# TM4C129ENCPDT register map
File version: 1.0
CPU: CORTEX_M4 1.0, other endian, MPU, FPU, 3 interrupt priority bits
Registers are 32-bit, read-write, reset 0x0 unless marked. A register's access mark holds for its fields unless they carry their own. Offsets are from the block's base; [hi:lo] are bit positions; {n}, {i} and the like mark numbered series.

## FLASH_CTRL — FLASH register offsets
Base 0x400FD000
0x00 FLASH_FMA — Flash Memory Address
  [19:0] FLASH_FMA_OFFSET — [19:0] Address Offset
0x04 FLASH_FMD — Flash Memory Data
  [31:0] FLASH_FMD_DATA — [31:0] Data Value
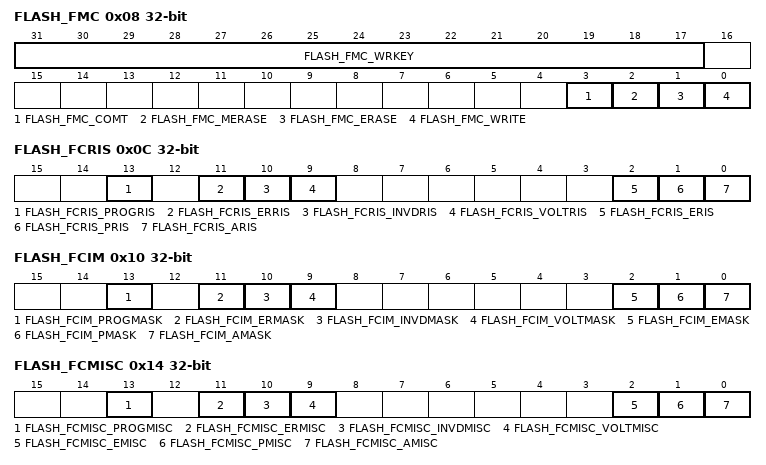
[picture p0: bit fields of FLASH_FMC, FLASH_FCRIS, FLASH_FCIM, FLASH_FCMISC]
0x08 FLASH_FMC — Flash Memory Control
  [31:17] FLASH_FMC_WRKEY — [31:17] FLASH write key
  [3] FLASH_FMC_COMT — [3:3] Commit Register Value
  [2] FLASH_FMC_MERASE — [2:2] Mass Erase Flash Memory
  [1] FLASH_FMC_ERASE — [1:1] Erase a Page of Flash Memory
  [0] FLASH_FMC_WRITE — [0:0] Write a Word into Flash Memory
0x0C FLASH_FCRIS — Flash Controller Raw Interrupt Status
  [13] FLASH_FCRIS_PROGRIS — [13:13] Program Verify Error Raw Interrupt Status
  [11] FLASH_FCRIS_ERRIS — [11:11] Erase Verify Error Raw Interrupt Status
  [10] FLASH_FCRIS_INVDRIS — [10:10] Invalid Data Raw Interrupt Status
  [9] FLASH_FCRIS_VOLTRIS — [9:9] Pump Voltage Raw Interrupt Status
  [2] FLASH_FCRIS_ERIS — [2:2] EEPROM Raw Interrupt Status
  [1] FLASH_FCRIS_PRIS — [1:1] Programming Raw Interrupt Status
  [0] FLASH_FCRIS_ARIS — [0:0] Access Raw Interrupt Status
0x10 FLASH_FCIM — Flash Controller Interrupt Mask
  [13] FLASH_FCIM_PROGMASK — [13:13] PROGVER Interrupt Mask
  [11] FLASH_FCIM_ERMASK — [11:11] ERVER Interrupt Mask
  [10] FLASH_FCIM_INVDMASK — [10:10] Invalid Data Interrupt Mask
  [9] FLASH_FCIM_VOLTMASK — [9:9] VOLT Interrupt Mask
  [2] FLASH_FCIM_EMASK — [2:2] EEPROM Interrupt Mask
  [1] FLASH_FCIM_PMASK — [1:1] Programming Interrupt Mask
  [0] FLASH_FCIM_AMASK — [0:0] Access Interrupt Mask
0x14 FLASH_FCMISC — Flash Controller Masked Interrupt Status and Clear
  [13] FLASH_FCMISC_PROGMISC — [13:13] PROGVER Masked Interrupt Status and Clear
  [11] FLASH_FCMISC_ERMISC — [11:11] ERVER Masked Interrupt Status and Clear
  [10] FLASH_FCMISC_INVDMISC — [10:10] Invalid Data Masked Interrupt Status and Clear
  [9] FLASH_FCMISC_VOLTMISC — [9:9] VOLT Masked Interrupt Status and Clear
  [2] FLASH_FCMISC_EMISC — [2:2] EEPROM Masked Interrupt Status and Clear
  [1] FLASH_FCMISC_PMISC — [1:1] Programming Masked Interrupt Status and Clear
  [0] FLASH_FCMISC_AMISC — [0:0] Access Masked Interrupt Status and Clear
0x20 FLASH_FMC2 — Flash Memory Control 2
  [0] FLASH_FMC2_WRBUF — [0:0] Buffered Flash Memory Write
0x30 FLASH_FWBVAL — Flash Write Buffer Valid
  [31:0] FLASH_FWBVAL_FWB — [31:0] Flash Memory Write Buffer
0x3C FLASH_FLPEKEY — Flash Program/Erase Key
  [15:0] FLASH_FLPEKEY_PEKEY — [15:0] Key Value
0x100 FLASH_FWBN — Flash Write Buffer n
  [31:0] FLASH_FWBN_DATA — [31:0] Data
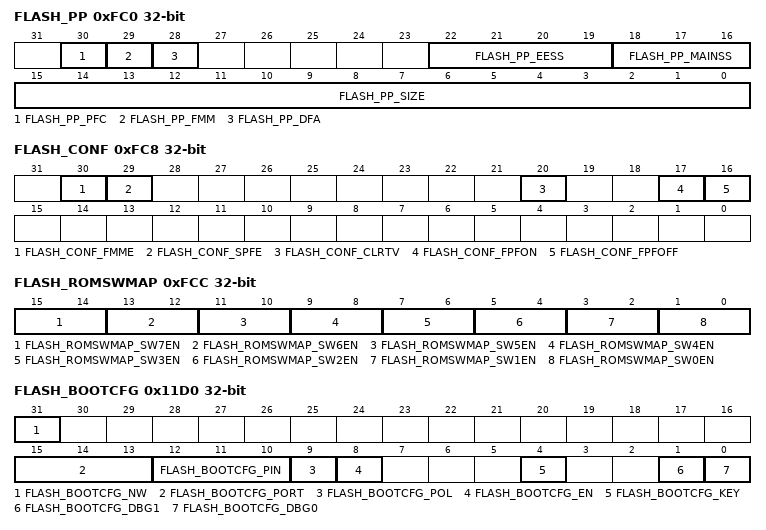
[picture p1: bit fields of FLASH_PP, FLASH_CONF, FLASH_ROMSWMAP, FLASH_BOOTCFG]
0xFC0 FLASH_PP — Flash Peripheral Properties
  [30] FLASH_PP_PFC — [30:30] Prefetch Buffer Mode
  [29] FLASH_PP_FMM — [29:29] Flash Mirror Mode
  [28] FLASH_PP_DFA — [28:28] DMA Flash Access
  [22:19] FLASH_PP_EESS — [22:19] EEPROM Sector Size of the physical bank
    0=FLASH_PP_EESS_1KB (1 KB); 0x80000=FLASH_PP_EESS_2KB (2 KB); 0x100000=FLASH_PP_EESS_4KB (4 KB); 0x180000=FLASH_PP_EESS_8KB (8 KB)
  [18:16] FLASH_PP_MAINSS — [18:16] Flash Sector Size of the physical bank
    0=FLASH_PP_MAINSS_1KB (1 KB); 0x10000=FLASH_PP_MAINSS_2KB (2 KB); 0x20000=FLASH_PP_MAINSS_4KB (4 KB); 0x30000=FLASH_PP_MAINSS_8KB (8 KB); 0x40000=FLASH_PP_MAINSS_16KB (16 KB)
  [15:0] FLASH_PP_SIZE — [15:0] Flash Size
    0x1FF=FLASH_PP_SIZE_1MB (1024 KB of Flash)
0xFC4 FLASH_SSIZE — SRAM Size
  [15:0] FLASH_SSIZE_SIZE — [15:0] SRAM Size
    0x3FF=FLASH_SSIZE_SIZE_256KB (256 KB of SRAM)
0xFC8 FLASH_CONF — Flash Configuration Register
  [30] FLASH_CONF_FMME — [30:30] Flash Mirror Mode Enable
  [29] FLASH_CONF_SPFE — [29:29] Single Prefetch Mode Enable
  [20] FLASH_CONF_CLRTV — [20:20] Clear Valid Tags
  [17] FLASH_CONF_FPFON — [17:17] Force Prefetch On
  [16] FLASH_CONF_FPFOFF — [16:16] Force Prefetch Off
0xFCC FLASH_ROMSWMAP — ROM Software Map
  [15:14] FLASH_ROMSWMAP_SW7EN — [15:14] ROM SW Region 7 Availability
    0=FLASH_ROMSWMAP_SW7EN_NOTVIS (Software region not available to the core); 0x4000=FLASH_ROMSWMAP_SW7EN_CORE (Region available to core)
  [13:12] FLASH_ROMSWMAP_SW6EN — [13:12] ROM SW Region 6 Availability
    0=FLASH_ROMSWMAP_SW6EN_NOTVIS (Software region not available to the core); 0x1000=FLASH_ROMSWMAP_SW6EN_CORE (Region available to core)
  [11:10] FLASH_ROMSWMAP_SW5EN — [11:10] ROM SW Region 5 Availability
    0=FLASH_ROMSWMAP_SW5EN_NOTVIS (Software region not available to the core); 0x400=FLASH_ROMSWMAP_SW5EN_CORE (Region available to core)
  [9:8] FLASH_ROMSWMAP_SW4EN — [9:8] ROM SW Region 4 Availability
    0=FLASH_ROMSWMAP_SW4EN_NOTVIS (Software region not available to the core); 0x100=FLASH_ROMSWMAP_SW4EN_CORE (Region available to core)
  [7:6] FLASH_ROMSWMAP_SW3EN — [7:6] ROM SW Region 3 Availability
    0=FLASH_ROMSWMAP_SW3EN_NOTVIS (Software region not available to the core); 64=FLASH_ROMSWMAP_SW3EN_CORE (Region available to core)
  [5:4] FLASH_ROMSWMAP_SW2EN — [5:4] ROM SW Region 2 Availability
    0=FLASH_ROMSWMAP_SW2EN_NOTVIS (Software region not available to the core); 16=FLASH_ROMSWMAP_SW2EN_CORE (Region available to core)
  [3:2] FLASH_ROMSWMAP_SW1EN — [3:2] ROM SW Region 1 Availability
    0=FLASH_ROMSWMAP_SW1EN_NOTVIS (Software region not available to the core); 4=FLASH_ROMSWMAP_SW1EN_CORE (Region available to core)
  [1:0] FLASH_ROMSWMAP_SW0EN — [1:0] ROM SW Region 0 Availability
    0=FLASH_ROMSWMAP_SW0EN_NOTVIS (Software region not available to the core); 1=FLASH_ROMSWMAP_SW0EN_CORE (Region available to core)
0xFD0 FLASH_DMASZ — Flash DMA Address Size
  [17:0] FLASH_DMASZ_SIZE — [17:0] uDMA-accessible Memory Size
0xFD4 FLASH_DMAST — Flash DMA Starting Address
  [28:11] FLASH_DMAST_ADDR — [28:11] Contains the starting address of the flash region accessible by uDMA if the FLASHPP register DFA bit is set
0x10D4 FLASH_RVP — Reset Vector Pointer
  [31:0] FLASH_RVP_RV — [31:0] Reset Vector Pointer Address
0x11D0 FLASH_BOOTCFG — Boot Configuration
  [31] FLASH_BOOTCFG_NW — [31:31] Not Written
  [15:13] FLASH_BOOTCFG_PORT — [15:13] Boot GPIO Port
    0=FLASH_BOOTCFG_PORT_A (Port A); 0x2000=FLASH_BOOTCFG_PORT_B (Port B); 0x4000=FLASH_BOOTCFG_PORT_C (Port C); 0x6000=FLASH_BOOTCFG_PORT_D (Port D); 0x8000=FLASH_BOOTCFG_PORT_E (Port E); 0xA000=FLASH_BOOTCFG_PORT_F (Port F); 0xC000=FLASH_BOOTCFG_PORT_G (Port G); 0xE000=FLASH_BOOTCFG_PORT_H (Port H)
  [12:10] FLASH_BOOTCFG_PIN — [12:10] Boot GPIO Pin
    0=Pin 0; 0x400=Pin 1; 0x800=Pin 2; 0xC00=Pin 3; 0x1000=Pin 4; 0x1400=Pin 5; 0x1800=Pin 6; 0x1C00=Pin 7
  [9] FLASH_BOOTCFG_POL — [9:9] Boot GPIO Polarity
  [8] FLASH_BOOTCFG_EN — [8:8] Boot GPIO Enable
  [4] FLASH_BOOTCFG_KEY — [4:4] KEY Select
  [1] FLASH_BOOTCFG_DBG1 — [1:1] Debug Control 1
  [0] FLASH_BOOTCFG_DBG0 — [0:0] Debug Control 0
{0x11E0+4i} FLASH_USERREG{i} (i=0..3) — User Register {i}
  [31:0] FLASH_USERREG{i}_DATA — [31:0] User Data
{0x1200+4i} FLASH_FMPRE{i} (i=0..7) — Flash Memory Protection Read Enable {i}
{0x1200+4i} FLASH_FMPRE{i} (i=8..15) — Flash Memory Protection Read Enable {i}
  [31:0] FLASH_FMPRE{i}_READ_ENABLE — [31:0] Flash Read Enable
{0x1400+4i} FLASH_FMPPE{i} (i=0..7) — Flash Memory Protection Program Enable {i}
{0x1400+4i} FLASH_FMPPE{i} (i=8..15) — Flash Memory Protection Program Enable {i}
  [31:0] FLASH_FMPPE{i}_PROG_ENABLE — [31:0] Flash Programming Enable
